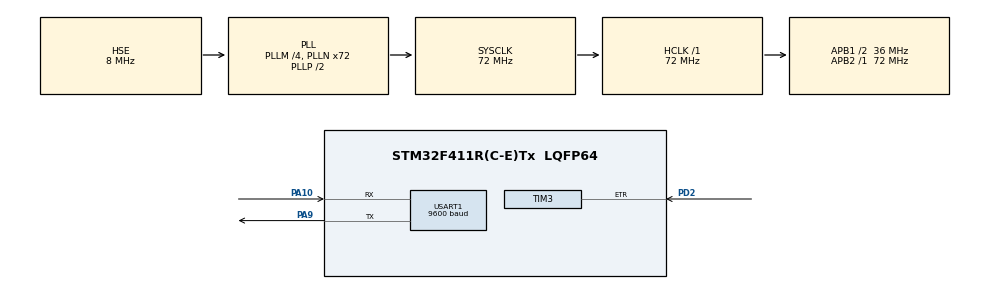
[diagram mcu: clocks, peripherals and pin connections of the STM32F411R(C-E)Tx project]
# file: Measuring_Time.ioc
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Mcu.Family=STM32F4
Mcu.Name=STM32F411R(C-E)Tx
Mcu.Package=LQFP64
NVIC.PriorityGroup=NVIC_PRIORITYGROUP_4
NVIC.TIM3_IRQn=true\:0\:0\:false\:false\:true\:true\:true\:true
NVIC.TIM4_IRQn=true\:0\:0\:false\:false\:true\:true\:true\:true
PA10.Mode=Asynchronous
PA10.Signal=USART1_RX
PA9.Mode=Asynchronous
PA9.Signal=USART1_TX
PD2.Signal=S_TIM3_ETR
PH0\ -\ OSC_IN.Mode=HSE-External-Oscillator
PH0\ -\ OSC_IN.Signal=RCC_OSC_IN
PH1\ -\ OSC_OUT.Mode=HSE-External-Oscillator
PH1\ -\ OSC_OUT.Signal=RCC_OSC_OUT
ProjectManager.HeapSize=0x200
ProjectManager.StackSize=0x400
ProjectManager.TargetToolchain=STM32CubeIDE
RCC.48MHZClocksFreq_Value=36000000
RCC.AHBFreq_Value=72000000
RCC.APB1CLKDivider=RCC_HCLK_DIV2
RCC.APB1Freq_Value=36000000
RCC.APB1TimFreq_Value=72000000
RCC.APB2Freq_Value=72000000
RCC.APB2TimFreq_Value=72000000
RCC.CortexFreq_Value=72000000
RCC.HCLKFreq_Value=72000000
RCC.HSE_VALUE=8000000
RCC.HSI_VALUE=16000000
RCC.LSE_VALUE=32768
RCC.PLLM=4
RCC.PLLN=72
RCC.PLLSourceVirtual=RCC_PLLSOURCE_HSE
RCC.SYSCLKFreq_VALUE=72000000
RCC.SYSCLKSource=RCC_SYSCLKSOURCE_PLLCLK
RCC.VCOOutputFreq_Value=144000000
SH.S_TIM3_ETR.0=TIM3_ETR,ClockSourceETR_Mode2
TIM3.AutoReloadPreload=TIM_AUTORELOAD_PRELOAD_ENABLE
TIM3.Period=65535
TIM3.Prescaler=0
TIM4.Period=36000
TIM4.Prescaler=100
USART1.BaudRate=9600
USART1.VirtualMode=VM_ASYNC
VP_TIM4_VS_ClockSourceINT.Mode=Internal
board=custom

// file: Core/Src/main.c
/* USER CODE BEGIN Header */
/**
  ******************************************************************************
  * @file           : main.c
  * @brief          : Main program body
  ******************************************************************************
  * @attention
  *
  * Copyright (c) 2022 STMicroelectronics.
  * All rights reserved.
  *
  * This software is licensed under terms that can be found in the LICENSE file
  * in the root directory of this software component.
  * If no LICENSE file comes with this software, it is provided AS-IS.
  *
  ******************************************************************************
  */
/* USER CODE END Header */
#include "main.h"

/* USER CODE BEGIN PTD */
uint32_t gu32_CounterTicks = 0x00;
uint32_t gu32_Freq = 0x00;
uint8_t gu8_MSG[40] = {'\0'};
/* USER CODE END PTD */

TIM_HandleTypeDef htim3;
TIM_HandleTypeDef htim4;

UART_HandleTypeDef huart1;

void SystemClock_Config(void);
static void MX_GPIO_Init(void);
static void MX_TIM3_Init(void);
static void MX_USART1_UART_Init(void);
static void MX_TIM4_Init(void);

int main(void)
{

  /* MCU Configuration--------------------------------------------------------*/

  /* Reset of all peripherals, Initializes the Flash interface and the Systick. */
  HAL_Init();

  /* Configure the system clock */
  SystemClock_Config();

  /* Initialize all configured peripherals */
  MX_GPIO_Init();
  MX_TIM3_Init();
  MX_USART1_UART_Init();
  MX_TIM4_Init();
  /* USER CODE BEGIN 2 */
  HAL_TIM_Base_Start_IT(&htim2);
  HAL_TIM_IC_Start_IT(&htim2, TIM_CHANNEL_1);
  /* USER CODE END 2 */

  /* Infinite loop */
  while (1)
  {

  }
}

void SystemClock_Config(void)
{
  RCC_OscInitTypeDef RCC_OscInitStruct = {0};
  RCC_ClkInitTypeDef RCC_ClkInitStruct = {0};

  /** Configure the main internal regulator output voltage
  */
  __HAL_RCC_PWR_CLK_ENABLE();
  __HAL_PWR_VOLTAGESCALING_CONFIG(PWR_REGULATOR_VOLTAGE_SCALE1);

  /** Initializes the RCC Oscillators according to the specified parameters
  * in the RCC_OscInitTypeDef structure.
  */
  RCC_OscInitStruct.OscillatorType = RCC_OSCILLATORTYPE_HSE;
  RCC_OscInitStruct.HSEState = RCC_HSE_ON;
  RCC_OscInitStruct.PLL.PLLState = RCC_PLL_ON;
  RCC_OscInitStruct.PLL.PLLSource = RCC_PLLSOURCE_HSE;
  RCC_OscInitStruct.PLL.PLLM = 4;
  RCC_OscInitStruct.PLL.PLLN = 72;
  RCC_OscInitStruct.PLL.PLLP = RCC_PLLP_DIV2;
  RCC_OscInitStruct.PLL.PLLQ = 4;
  if (HAL_RCC_OscConfig(&RCC_OscInitStruct) != HAL_OK)
  {
    Error_Handler();
  }

  /** Initializes the CPU, AHB and APB buses clocks
  */
  RCC_ClkInitStruct.ClockType = RCC_CLOCKTYPE_HCLK|RCC_CLOCKTYPE_SYSCLK
                              |RCC_CLOCKTYPE_PCLK1|RCC_CLOCKTYPE_PCLK2;
  RCC_ClkInitStruct.SYSCLKSource = RCC_SYSCLKSOURCE_PLLCLK;
  RCC_ClkInitStruct.AHBCLKDivider = RCC_SYSCLK_DIV1;
  RCC_ClkInitStruct.APB1CLKDivider = RCC_HCLK_DIV2;
  RCC_ClkInitStruct.APB2CLKDivider = RCC_HCLK_DIV1;

  if (HAL_RCC_ClockConfig(&RCC_ClkInitStruct, FLASH_LATENCY_2) != HAL_OK)
  {
    Error_Handler();
  }
}

static void MX_TIM3_Init(void)
{

  TIM_ClockConfigTypeDef sClockSourceConfig = {0};
  TIM_MasterConfigTypeDef sMasterConfig = {0};

  htim3.Instance = TIM3;
  htim3.Init.Prescaler = 0;
  htim3.Init.CounterMode = TIM_COUNTERMODE_UP;
  htim3.Init.Period = 65535;
  htim3.Init.ClockDivision = TIM_CLOCKDIVISION_DIV1;
  htim3.Init.AutoReloadPreload = TIM_AUTORELOAD_PRELOAD_ENABLE;
  if (HAL_TIM_Base_Init(&htim3) != HAL_OK)
  {
    Error_Handler();
  }
  sClockSourceConfig.ClockSource = TIM_CLOCKSOURCE_ETRMODE2;
  sClockSourceConfig.ClockPolarity = TIM_CLOCKPOLARITY_NONINVERTED;
  sClockSourceConfig.ClockPrescaler = TIM_CLOCKPRESCALER_DIV1;
  sClockSourceConfig.ClockFilter = 0;
  if (HAL_TIM_ConfigClockSource(&htim3, &sClockSourceConfig) != HAL_OK)
  {
    Error_Handler();
  }
  sMasterConfig.MasterOutputTrigger = TIM_TRGO_RESET;
  sMasterConfig.MasterSlaveMode = TIM_MASTERSLAVEMODE_DISABLE;
  if (HAL_TIMEx_MasterConfigSynchronization(&htim3, &sMasterConfig) != HAL_OK)
  {
    Error_Handler();
  }

}

static void MX_TIM4_Init(void)
{

  TIM_ClockConfigTypeDef sClockSourceConfig = {0};
  TIM_MasterConfigTypeDef sMasterConfig = {0};

  htim4.Instance = TIM4;
  htim4.Init.Prescaler = 100;
  htim4.Init.CounterMode = TIM_COUNTERMODE_UP;
  htim4.Init.Period = 36000;
  htim4.Init.ClockDivision = TIM_CLOCKDIVISION_DIV1;
  htim4.Init.AutoReloadPreload = TIM_AUTORELOAD_PRELOAD_DISABLE;
  if (HAL_TIM_Base_Init(&htim4) != HAL_OK)
  {
    Error_Handler();
  }
  sClockSourceConfig.ClockSource = TIM_CLOCKSOURCE_INTERNAL;
  if (HAL_TIM_ConfigClockSource(&htim4, &sClockSourceConfig) != HAL_OK)
  {
    Error_Handler();
  }
  sMasterConfig.MasterOutputTrigger = TIM_TRGO_RESET;
  sMasterConfig.MasterSlaveMode = TIM_MASTERSLAVEMODE_DISABLE;
  if (HAL_TIMEx_MasterConfigSynchronization(&htim4, &sMasterConfig) != HAL_OK)
  {
    Error_Handler();
  }

}

static void MX_USART1_UART_Init(void)
{

  huart1.Instance = USART1;
  huart1.Init.BaudRate = 9600;
  huart1.Init.WordLength = UART_WORDLENGTH_8B;
  huart1.Init.StopBits = UART_STOPBITS_1;
  huart1.Init.Parity = UART_PARITY_NONE;
  huart1.Init.Mode = UART_MODE_TX_RX;
  huart1.Init.HwFlowCtl = UART_HWCONTROL_NONE;
  huart1.Init.OverSampling = UART_OVERSAMPLING_16;
  if (HAL_UART_Init(&huart1) != HAL_OK)
  {
    Error_Handler();
  }

}

static void MX_GPIO_Init(void)
{

  /* GPIO Ports Clock Enable */
  __HAL_RCC_GPIOH_CLK_ENABLE();
  __HAL_RCC_GPIOA_CLK_ENABLE();
  __HAL_RCC_GPIOD_CLK_ENABLE();

}

/* USER CODE BEGIN 4 */
void HAL_TIM_IC_CaptureCallback(TIM_HandleTypeDef* htim)
{
    if(gu8_State == IDLE)
    {
        gu32_T1 = TIM2->CCR1;
        gu16_TIM2_OVC = 0;
        gu8_State = DONE;
    }
    else if(gu8_State == DONE)
    {
        gu32_T2 = TIM2->CCR1;
        gu32_Ticks = (gu32_T2 + (gu16_TIM2_OVC * 65536)) - gu32_T1;
        gu32_Freq = (uint32_t)(F_CLK/gu32_Ticks);
        if(gu32_Freq != 0)
        {
          sprintf(gu8_MSG, "Frequency = %lu Hz\n\r", gu32_Freq);
          HAL_UART_Transmit(&huart1, gu8_MSG, sizeof(gu8_MSG), 100);
        }
        gu8_State = IDLE;
    }
}

void HAL_TIM_PeriodElapsedCallback(TIM_HandleTypeDef* htim)
{
    gu16_TIM2_OVC++;
}
/* USER CODE END 4 */

void Error_Handler(void)
{
  __disable_irq();
  while (1)
  {
  }
}
